# STM32F0x2 register map
File version: 1.3
CPU: CM0 r0p0, little endian, no MPU, no FPU, 2 interrupt priority bits
Registers are 32-bit, read-write, reset 0x0 unless marked. A register's access mark holds for its fields unless they carry their own. Offsets are from the block's base; [hi:lo] are bit positions; {n}, {i} and the like mark numbered series.

## GPIOF — General-purpose I/Os
Base 0x48001400
Same registers: GPIOB 0x48000400, GPIOC 0x48000800, GPIOD 0x48000C00, GPIOE 0x48001000
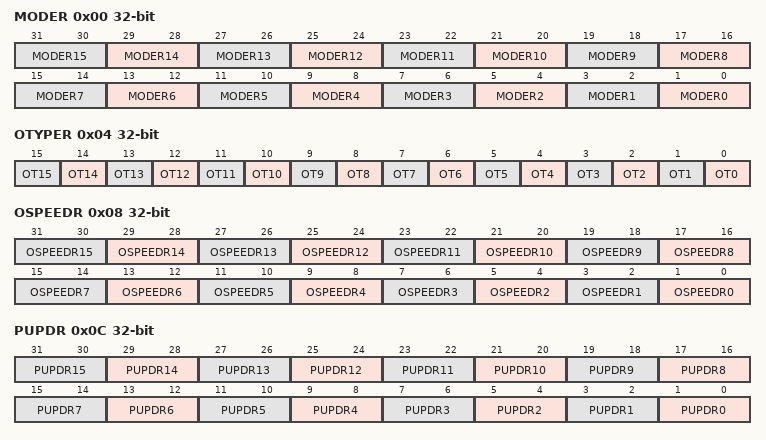
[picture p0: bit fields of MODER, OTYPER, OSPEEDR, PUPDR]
0x00 MODER — GPIO port mode register
  [2n+1:2n] MODER{n} (n=0..15) — Port x configuration pin {n}
    0=Input mode (reset state); 1=Output (General purpose output mode); 2=Alternate function mode; 3=Analog mode
0x04 OTYPER — GPIO port output type register
  [n] OT{n} (n=0..15) — Port x configuration pin {n}
    0=PushPull (Output push-pull (reset state)); 1=OpenDrain (Output open-drain)
0x08 OSPEEDR — GPIO port output speed register
  [2n+1:2n] OSPEEDR{n} (n=0..15) — Port x configuration pin {n}
    0=LowSpeed; 1=MediumSpeed; 2=HighSpeed; 3=VeryHighSpeed
0x0C PUPDR — GPIO port pull-up/pull-down register
  [2n+1:2n] PUPDR{n} (n=0..15) — Port x configuration pin {n}
    0=Floating (No pull-up, pull-down); 1=PullUp; 2=PullDown
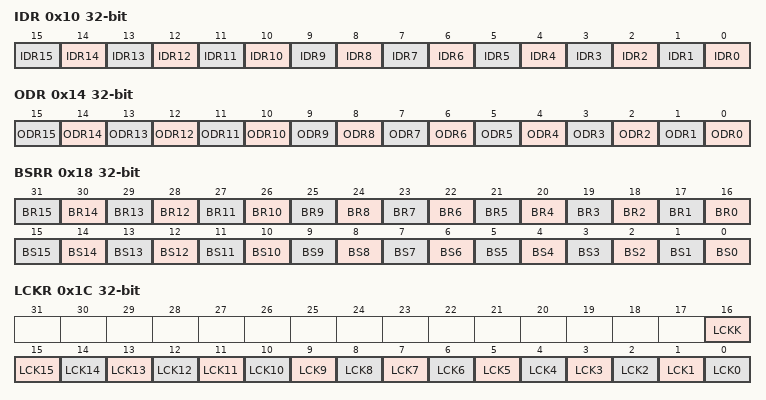
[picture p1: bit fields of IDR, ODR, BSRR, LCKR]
0x10 IDR ro — GPIO port input data register
  [n] IDR{n} (n=0..15) — Port input data pin {n}
    0=Low (Input is logic low); 1=High (Input is logic high)
0x14 ODR — GPIO port output data register
  [n] ODR{n} (n=0..15) — Port output data pin {n}
    0=Low (Set output to logic low); 1=High (Set output to logic high)
0x18 BSRR wo — GPIO port bit set/reset register
  [n+16] BR{n} (n=0..15) — Port x reset pin {n}
    1=Resets the corresponding ODRx bit
  [n] BS{n} (n=0..15) — Port x set pin {n}
    1=Set (Sets the corresponding ODRx bit)
0x1C LCKR — GPIO port configuration lock register
  [16] LCKK — Port x lock bit y (y= 0..15)
    0=NotActive (Port configuration lock key not active); 1=Active (Port configuration lock key active)
  [n] LCK{n} (n=0..15) — Port x lock pin {n}
    0=Unlocked (Port configuration not locked); 1=Locked (Port configuration locked)
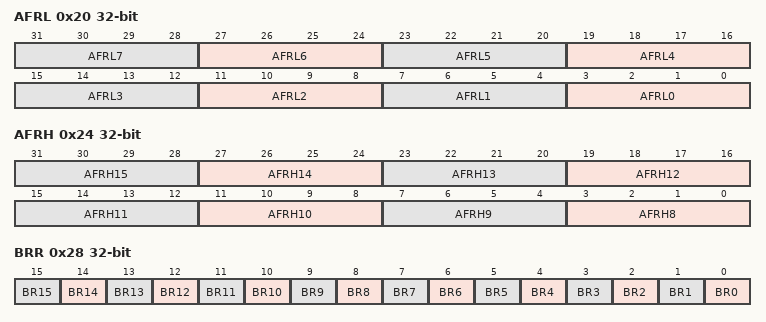
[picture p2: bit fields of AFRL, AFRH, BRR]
0x20 AFRL — GPIO alternate function low register
  [3:0] AFR{x} (x=L0,L1,L2,L3,L4,L5,L6,L7; step 4) — Alternate function selection for port x bit y (y = 0..7)
    {v}=AF{v} (v=0..15)
0x24 AFRH — GPIO alternate function high register
  [3:0] AFR{x} (x=H8,H9,H10,H11,H12,H13,H14,H15; step 4) — Alternate function selection for port x bit y (y = 8..15)
    {v}=AF{v} (v=0..15)
0x28 BRR wo — Port bit reset register
  [n] BR{n} (n=0..15) — Port x reset pin {n}
    0=No action on the corresponding ODx bit; 1=Reset the ODx bit

## GPIOA — General-purpose I/Os
Base 0x48000000
Registers as GPIOF; these are added or differ:
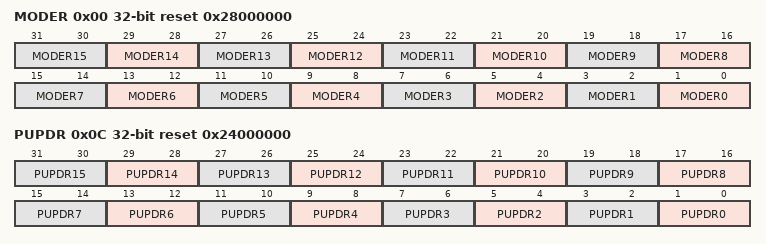
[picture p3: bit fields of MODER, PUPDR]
0x00 MODER reset 0x28000000 — GPIO port mode register
  [2n+1:2n] MODER{n} (n=0..15) — Port x configuration pin {n}
    0=Input mode (reset state); 1=Output (General purpose output mode); 2=Alternate function mode; 3=Analog mode
0x0C PUPDR reset 0x24000000 — GPIO port pull-up/pull-down register
  [2n+1:2n] PUPDR{n} (n=0..15) — Port x configuration pin {n}
    0=Floating (No pull-up, pull-down); 1=PullUp; 2=PullDown

## PWR — Power control
Base 0x40007000
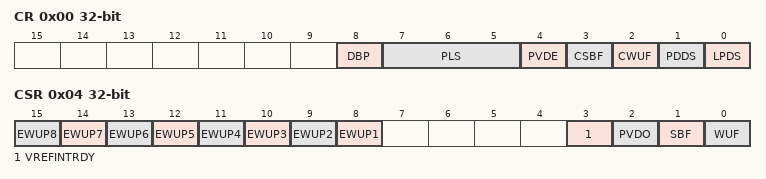
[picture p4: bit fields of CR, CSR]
0x00 CR — power control register
  [8] DBP — Disable backup domain write protection
  [7:5] PLS — PVD level selection
  [4] PVDE — Power voltage detector enable
  [3] CSBF — Clear standby flag
  [2] CWUF — Clear wakeup flag
  [1] PDDS — Power down deepsleep
    0=STOP_MODE (Enter Stop mode when the CPU enters deepsleep); 1=STANDBY_MODE (Enter Standby mode when the CPU enters deepsleep)
  [0] LPDS — Low-power deep sleep
0x04 CSR access per field — power control/status register
  [n+7] EWUP{n} rw (n=1..8) — Enable WKUP pin {n}
  [3] VREFINTRDY ro — VREFINT reference voltage ready
  [2] PVDO ro — PVD output
  [1] SBF ro — Standby flag
  [0] WUF ro — Wakeup flag

## IWDG — Independent watchdog
Base 0x40003000
0x00 KR 16-bit wo — Key register
  [15:0] KEY — Key value
    0x5555=Unlock (Enable access to PR, RLR and WINR registers); 0xAAAA=Feed watchdog with RLR register value; 0xCCCC=Start the watchdog
0x04 PR 16-bit — Prescaler register
  [2:0] PR — Prescaler divider
    0=DivideBy4 (Divider /4); 1=DivideBy8 (Divider /8); 2=DivideBy16 (Divider /16); 3=DivideBy32 (Divider /32); 4=DivideBy64 (Divider /64); 5=DivideBy128 (Divider /128); other=DivideBy256 (Divider /256)
0x08 RLR 16-bit reset 0xFFF — Reload register
  [11:0] RL — Watchdog counter reload value
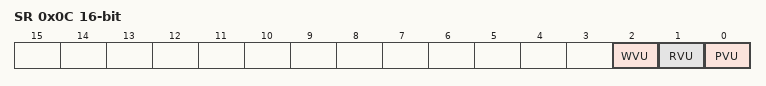
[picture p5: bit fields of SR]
0x0C SR 16-bit ro — Status register
  [2] WVU — Watchdog counter window value update
  [1] RVU — Watchdog counter reload value update
  [0] PVU — Watchdog prescaler value update
0x10 WINR 16-bit reset 0xFFF — Window register
  [11:0] WIN — Watchdog counter window value
